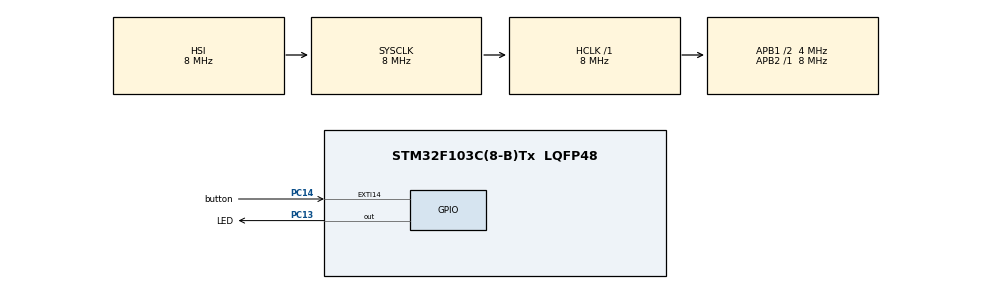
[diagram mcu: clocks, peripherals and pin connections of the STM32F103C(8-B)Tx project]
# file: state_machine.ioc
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Mcu.Family=STM32F1
Mcu.Name=STM32F103C(8-B)Tx
Mcu.Package=LQFP48
NVIC.EXTI15_10_IRQn=true\:0\:0\:false\:false\:true\:true\:true\:true
NVIC.PriorityGroup=NVIC_PRIORITYGROUP_4
PA13.Mode=JTAG_4_pins
PA13.Signal=SYS_JTMS-SWDIO
PA14.Mode=JTAG_4_pins
PA14.Signal=SYS_JTCK-SWCLK
PA15.Mode=JTAG_4_pins
PA15.Signal=SYS_JTDI
PB3.Mode=JTAG_4_pins
PB3.Signal=SYS_JTDO-TRACESWO
PC13-TAMPER-RTC.GPIO_Label=LED
PC13-TAMPER-RTC.Signal=GPIO_Output
PC14-OSC32_IN.GPIO_Label=button
PC14-OSC32_IN.GPIO_ModeDefaultEXTI=GPIO_MODE_IT_FALLING
PC14-OSC32_IN.GPIO_PuPd=GPIO_PULLUP
PC14-OSC32_IN.Signal=GPXTI14
ProjectManager.HeapSize=0x200
ProjectManager.StackSize=0x400
ProjectManager.TargetToolchain=STM32CubeIDE
RCC.AHBFreq_Value=8000000
RCC.APB1CLKDivider=RCC_HCLK_DIV2
RCC.APB1Freq_Value=4000000
RCC.APB1TimFreq_Value=8000000
RCC.APB2Freq_Value=8000000
RCC.APB2TimFreq_Value=8000000
RCC.HCLKFreq_Value=8000000
RCC.PLLMUL=RCC_PLL_MUL16
RCC.SYSCLKFreq_VALUE=8000000
RCC.USBFreq_Value=64000000
board=custom

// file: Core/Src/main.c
/* USER CODE BEGIN Header */
/**
  ******************************************************************************
  * @file           : main.c
  * @brief          : Main program body
  ******************************************************************************
  * @attention
  *
  * Copyright (c) 2022 STMicroelectronics.
  * All rights reserved.
  *
  * This software is licensed under terms that can be found in the LICENSE file
  * in the root directory of this software component.
  * If no LICENSE file comes with this software, it is provided AS-IS.
  *
  ******************************************************************************
  */
/* USER CODE END Header */
#include "main.h"

/* USER CODE BEGIN Includes */
#include "Statechart_required.h"
/* USER CODE END Includes */

/* USER CODE BEGIN PV */
Statechart statechart;
/* USER CODE END PV */

void SystemClock_Config(void);
static void MX_GPIO_Init(void);
/* USER CODE BEGIN PFP */

void HAL_GPIO_EXTI_Callback(uint16_t GPIO_Pin)
{
  if (button_Pin == GPIO_Pin)
  {
	  statechart_raise_buttonPushed( &statechart );
  }
}

void statechart_onLED( Statechart* handle)
{
	HAL_GPIO_WritePin( LED_GPIO_Port, LED_Pin, GPIO_PIN_SET );
}

void statechart_offLED( Statechart* handle)
{
	HAL_GPIO_WritePin( LED_GPIO_Port, LED_Pin, GPIO_PIN_RESET );
}

/* USER CODE END PFP */

int main(void)
{

  /* MCU Configuration--------------------------------------------------------*/

  /* Reset of all peripherals, Initializes the Flash interface and the Systick. */
  HAL_Init();

  /* Configure the system clock */
  SystemClock_Config();

  /* Initialize all configured peripherals */
  MX_GPIO_Init();
  /* USER CODE BEGIN 2 */
  statechart_init( &statechart );
  statechart_enter( &statechart );
  /* USER CODE END 2 */

  /* Infinite loop */
  while (1)
  {

  }
}

void SystemClock_Config(void)
{
  RCC_OscInitTypeDef RCC_OscInitStruct = {0};
  RCC_ClkInitTypeDef RCC_ClkInitStruct = {0};

  /** Initializes the RCC Oscillators according to the specified parameters
  * in the RCC_OscInitTypeDef structure.
  */
  RCC_OscInitStruct.OscillatorType = RCC_OSCILLATORTYPE_HSI;
  RCC_OscInitStruct.HSIState = RCC_HSI_ON;
  RCC_OscInitStruct.HSICalibrationValue = RCC_HSICALIBRATION_DEFAULT;
  RCC_OscInitStruct.PLL.PLLState = RCC_PLL_NONE;
  if (HAL_RCC_OscConfig(&RCC_OscInitStruct) != HAL_OK)
  {
    Error_Handler();
  }

  /** Initializes the CPU, AHB and APB buses clocks
  */
  RCC_ClkInitStruct.ClockType = RCC_CLOCKTYPE_HCLK|RCC_CLOCKTYPE_SYSCLK
                              |RCC_CLOCKTYPE_PCLK1|RCC_CLOCKTYPE_PCLK2;
  RCC_ClkInitStruct.SYSCLKSource = RCC_SYSCLKSOURCE_HSI;
  RCC_ClkInitStruct.AHBCLKDivider = RCC_SYSCLK_DIV1;
  RCC_ClkInitStruct.APB1CLKDivider = RCC_HCLK_DIV2;
  RCC_ClkInitStruct.APB2CLKDivider = RCC_HCLK_DIV1;

  if (HAL_RCC_ClockConfig(&RCC_ClkInitStruct, FLASH_LATENCY_0) != HAL_OK)
  {
    Error_Handler();
  }
}

static void MX_GPIO_Init(void)
{
  GPIO_InitTypeDef GPIO_InitStruct = {0};

  /* GPIO Ports Clock Enable */
  __HAL_RCC_GPIOC_CLK_ENABLE();
  __HAL_RCC_GPIOA_CLK_ENABLE();
  __HAL_RCC_GPIOB_CLK_ENABLE();

  /*Configure GPIO pin Output Level */
  HAL_GPIO_WritePin(LED_GPIO_Port, LED_Pin, GPIO_PIN_RESET);

  /*Configure GPIO pin : LED_Pin */
  GPIO_InitStruct.Pin = LED_Pin;
  GPIO_InitStruct.Mode = GPIO_MODE_OUTPUT_PP;
  GPIO_InitStruct.Pull = GPIO_NOPULL;
  GPIO_InitStruct.Speed = GPIO_SPEED_FREQ_LOW;
  HAL_GPIO_Init(LED_GPIO_Port, &GPIO_InitStruct);

  /*Configure GPIO pin : button_Pin */
  GPIO_InitStruct.Pin = button_Pin;
  GPIO_InitStruct.Mode = GPIO_MODE_IT_FALLING;
  GPIO_InitStruct.Pull = GPIO_PULLUP;
  HAL_GPIO_Init(button_GPIO_Port, &GPIO_InitStruct);

  /* EXTI interrupt init*/
  HAL_NVIC_SetPriority(EXTI15_10_IRQn, 0, 0);
  HAL_NVIC_EnableIRQ(EXTI15_10_IRQn);

}

void Error_Handler(void)
{
  __disable_irq();
  while (1)
  {
  }
}
